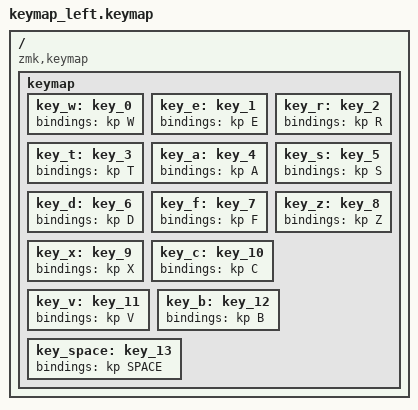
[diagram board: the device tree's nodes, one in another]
/ { compatible = "zmk,keymap"; keymap {
        key_w: key_0 { bindings = <&kp W>; };
        key_e: key_1 { bindings = <&kp E>; };
        key_r: key_2 { bindings = <&kp R>; };
        key_t: key_3 { bindings = <&kp T>; };
        key_a: key_4 { bindings = <&kp A>; };
        key_s: key_5 { bindings = <&kp S>; };
        key_d: key_6 { bindings = <&kp D>; };
        key_f: key_7 { bindings = <&kp F>; };
        key_z: key_8 { bindings = <&kp Z>; };
        key_x: key_9 { bindings = <&kp X>; };
        key_c: key_10 { bindings = <&kp C>; };
        key_v: key_11 { bindings = <&kp V>; };
        key_b: key_12 { bindings = <&kp B>; };
        key_space: key_13 { bindings = <&kp SPACE>; };
    };
};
